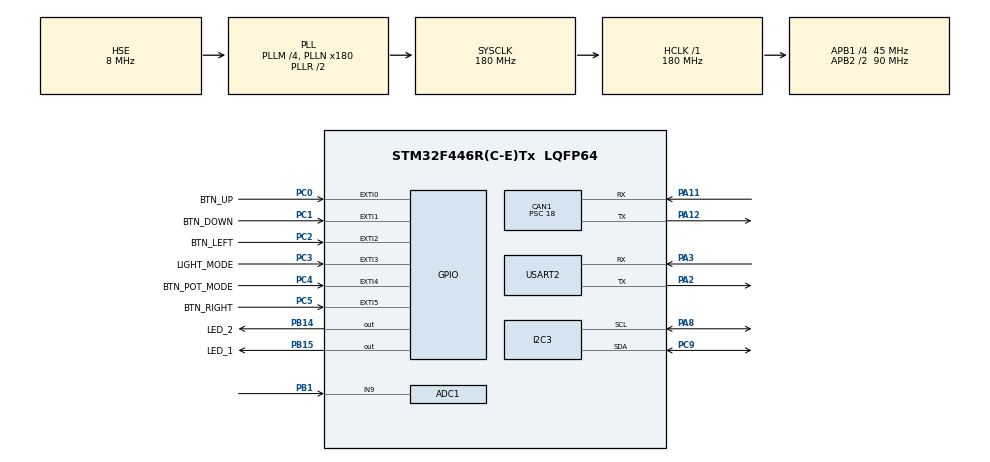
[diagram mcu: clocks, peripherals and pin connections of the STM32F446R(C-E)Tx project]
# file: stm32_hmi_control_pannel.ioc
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ADC1.Channel-0\#ChannelRegularConversion=ADC_CHANNEL_9
ADC1.ClockPrescaler=ADC_CLOCK_SYNC_PCLK_DIV8
ADC1.ContinuousConvMode=ENABLE
ADC1.DMAContinuousRequests=ENABLE
ADC1.EOCSelection=ADC_EOC_SINGLE_CONV
ADC1.NbrOfConversionFlag=1
ADC1.Rank-0\#ChannelRegularConversion=1
ADC1.SamplingTime-0\#ChannelRegularConversion=ADC_SAMPLETIME_3CYCLES
ADC1.ScanConvMode=DISABLE
ADC1.master=1
CAN1.BS1=CAN_BS1_2TQ
CAN1.BS2=CAN_BS2_2TQ
CAN1.CalculateBaudRate=500000
CAN1.CalculateTimeBit=2000
CAN1.CalculateTimeQuantum=400.0
CAN1.Prescaler=18
Dma.ADC1.0.Direction=DMA_PERIPH_TO_MEMORY
Dma.ADC1.0.FIFOMode=DMA_FIFOMODE_DISABLE
Dma.ADC1.0.Instance=DMA2_Stream0
Dma.ADC1.0.MemDataAlignment=DMA_MDATAALIGN_HALFWORD
Dma.ADC1.0.MemInc=DMA_MINC_ENABLE
Dma.ADC1.0.Mode=DMA_CIRCULAR
Dma.ADC1.0.PeriphDataAlignment=DMA_PDATAALIGN_HALFWORD
Dma.ADC1.0.PeriphInc=DMA_PINC_DISABLE
Dma.ADC1.0.Priority=DMA_PRIORITY_LOW
Dma.Request0=ADC1
I2C3.I2C_Mode=I2C_Fast
Mcu.Family=STM32F4
Mcu.Name=STM32F446R(C-E)Tx
Mcu.Package=LQFP64
NVIC.DMA2_Stream0_IRQn=true\:0\:0\:false\:false\:true\:false\:true\:true
NVIC.EXTI0_IRQn=true\:0\:0\:false\:false\:true\:true\:true\:true
NVIC.EXTI1_IRQn=true\:0\:0\:false\:false\:true\:true\:true\:true
NVIC.EXTI2_IRQn=true\:0\:0\:false\:false\:true\:true\:true\:true
NVIC.EXTI3_IRQn=true\:0\:0\:false\:false\:true\:true\:true\:true
NVIC.EXTI4_IRQn=true\:0\:0\:false\:false\:true\:true\:true\:true
NVIC.EXTI9_5_IRQn=true\:0\:0\:false\:false\:true\:true\:true\:true
NVIC.PriorityGroup=NVIC_PRIORITYGROUP_4
PA11.Mode=CAN_Activate
PA11.Signal=CAN1_RX
PA12.Mode=CAN_Activate
PA12.Signal=CAN1_TX
PA13.Mode=Serial_Wire
PA13.Signal=SYS_JTMS-SWDIO
PA14.Mode=Serial_Wire
PA14.Signal=SYS_JTCK-SWCLK
PA2.Mode=Asynchronous
PA2.Signal=USART2_TX
PA3.Mode=Asynchronous
PA3.Signal=USART2_RX
PA8.Mode=I2C
PA8.Signal=I2C3_SCL
PB1.Signal=ADCx_IN9
PB14.GPIO_Label=LED_2
PB14.Signal=GPIO_Output
PB15.GPIO_Label=LED_1
PB15.Signal=GPIO_Output
PC0.GPIO_Label=BTN_UP
PC0.GPIO_ModeDefaultEXTI=GPIO_MODE_IT_FALLING
PC0.GPIO_PuPd=GPIO_PULLUP
PC0.Signal=GPXTI0
PC1.GPIO_Label=BTN_DOWN
PC1.GPIO_ModeDefaultEXTI=GPIO_MODE_IT_FALLING
PC1.GPIO_PuPd=GPIO_PULLUP
PC1.Signal=GPXTI1
PC2.GPIO_Label=BTN_LEFT
PC2.GPIO_ModeDefaultEXTI=GPIO_MODE_IT_FALLING
PC2.GPIO_PuPd=GPIO_PULLUP
PC2.Signal=GPXTI2
PC3.GPIO_Label=LIGHT_MODE
PC3.GPIO_ModeDefaultEXTI=GPIO_MODE_IT_FALLING
PC3.GPIO_PuPd=GPIO_PULLUP
PC3.Signal=GPXTI3
PC4.GPIO_Label=BTN_POT_MODE
PC4.GPIO_ModeDefaultEXTI=GPIO_MODE_IT_FALLING
PC4.GPIO_PuPd=GPIO_PULLUP
PC4.Signal=GPXTI4
PC5.GPIO_Label=BTN_RIGHT
PC5.GPIO_ModeDefaultEXTI=GPIO_MODE_IT_FALLING
PC5.GPIO_PuPd=GPIO_PULLUP
PC5.Signal=GPXTI5
PC9.Mode=I2C
PC9.Signal=I2C3_SDA
PH0-OSC_IN.Mode=HSE-External-Oscillator
PH0-OSC_IN.Signal=RCC_OSC_IN
PH1-OSC_OUT.Mode=HSE-External-Oscillator
PH1-OSC_OUT.Signal=RCC_OSC_OUT
ProjectManager.HeapSize=0x200
ProjectManager.StackSize=0x400
ProjectManager.TargetToolchain=CMake
RCC.AHBFreq_Value=180000000
RCC.APB1CLKDivider=RCC_HCLK_DIV4
RCC.APB1Freq_Value=45000000
RCC.APB1TimFreq_Value=90000000
RCC.APB2CLKDivider=RCC_HCLK_DIV2
RCC.APB2Freq_Value=90000000
RCC.APB2TimFreq_Value=180000000
RCC.CortexFreq_Value=180000000
RCC.HCLKFreq_Value=180000000
RCC.HSE_VALUE=8000000
RCC.PLLM=4
RCC.PLLN=180
RCC.PLLSourceVirtual=RCC_PLLSOURCE_HSE
RCC.SYSCLKFreq_VALUE=180000000
RCC.SYSCLKSource=RCC_SYSCLKSOURCE_PLLRCLK
RCC.USBFreq_Value=180000000
RCC.VCOOutputFreq_Value=360000000
SH.ADCx_IN9.0=ADC1_IN9,IN9
TIM13.ClockDivision=TIM_CLOCKDIVISION_DIV1
TIM13.Prescaler=17999
TIM14.Prescaler=8999
USART2.VirtualMode=VM_ASYNC
VP_TIM13_VS_ClockSourceINT.Mode=Enable_Timer
VP_TIM14_VS_ClockSourceINT.Mode=Enable_Timer
board=custom

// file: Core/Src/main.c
/* USER CODE BEGIN Header */
/**
  ******************************************************************************
  * @file           : main.c
  * @brief          : Main program body
  ******************************************************************************
  * @attention
  *
  * Copyright (c) 2025 STMicroelectronics.
  * All rights reserved.
  *
  * This software is licensed under terms that can be found in the LICENSE file
  * in the root directory of this software component.
  * If no LICENSE file comes with this software, it is provided AS-IS.
  *
  ******************************************************************************
  */
/* USER CODE END Header */
#include "main.h"
#include "adc.h"
#include "can.h"
#include "dma.h"
#include "i2c.h"
#include "tim.h"
#include "usart.h"
#include "gpio.h"

/* USER CODE BEGIN Includes */
#include <stdio.h>
#include "app.h"
/* USER CODE END Includes */

void SystemClock_Config(void);

int main(void)
{

  /* MCU Configuration--------------------------------------------------------*/

  /* Reset of all peripherals, Initializes the Flash interface and the Systick. */
  HAL_Init();

  /* Configure the system clock */
  SystemClock_Config();

  /* Initialize all configured peripherals */
  MX_GPIO_Init();
  MX_DMA_Init();
  MX_USART2_UART_Init();
  MX_ADC1_Init();
  MX_I2C3_Init();
  MX_CAN1_Init();
  MX_TIM14_Init();
  MX_TIM13_Init();

  /* Infinite loop */
  /* USER CODE BEGIN WHILE */

  app(); // Main app function

  while (1)
  {
    /* USER CODE END WHILE */

  }
}

void SystemClock_Config(void)
{
  RCC_OscInitTypeDef RCC_OscInitStruct = {0};
  RCC_ClkInitTypeDef RCC_ClkInitStruct = {0};

  /** Configure the main internal regulator output voltage
  */
  __HAL_RCC_PWR_CLK_ENABLE();
  __HAL_PWR_VOLTAGESCALING_CONFIG(PWR_REGULATOR_VOLTAGE_SCALE1);

  /** Initializes the RCC Oscillators according to the specified parameters
  * in the RCC_OscInitTypeDef structure.
  */
  RCC_OscInitStruct.OscillatorType = RCC_OSCILLATORTYPE_HSE;
  RCC_OscInitStruct.HSEState = RCC_HSE_ON;
  RCC_OscInitStruct.PLL.PLLState = RCC_PLL_ON;
  RCC_OscInitStruct.PLL.PLLSource = RCC_PLLSOURCE_HSE;
  RCC_OscInitStruct.PLL.PLLM = 4;
  RCC_OscInitStruct.PLL.PLLN = 180;
  RCC_OscInitStruct.PLL.PLLP = RCC_PLLP_DIV2;
  RCC_OscInitStruct.PLL.PLLQ = 2;
  RCC_OscInitStruct.PLL.PLLR = 2;
  if (HAL_RCC_OscConfig(&RCC_OscInitStruct) != HAL_OK)
  {
    Error_Handler();
  }

  /** Activate the Over-Drive mode
  */
  if (HAL_PWREx_EnableOverDrive() != HAL_OK)
  {
    Error_Handler();
  }

  /** Initializes the CPU, AHB and APB buses clocks
  */
  RCC_ClkInitStruct.ClockType = RCC_CLOCKTYPE_HCLK|RCC_CLOCKTYPE_SYSCLK
                              |RCC_CLOCKTYPE_PCLK1|RCC_CLOCKTYPE_PCLK2;
  RCC_ClkInitStruct.SYSCLKSource = RCC_SYSCLKSOURCE_PLLRCLK;
  RCC_ClkInitStruct.AHBCLKDivider = RCC_SYSCLK_DIV1;
  RCC_ClkInitStruct.APB1CLKDivider = RCC_HCLK_DIV4;
  RCC_ClkInitStruct.APB2CLKDivider = RCC_HCLK_DIV2;

  if (HAL_RCC_ClockConfig(&RCC_ClkInitStruct, FLASH_LATENCY_5) != HAL_OK)
  {
    Error_Handler();
  }
}

void Error_Handler(void)
{
  __disable_irq();
  while (1)
  {
  }
}
